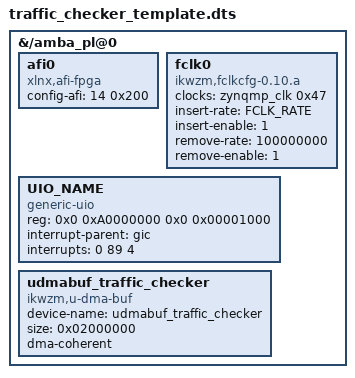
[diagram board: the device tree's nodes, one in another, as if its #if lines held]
#ifndef FPGA_REGION
#error "FPGA_REGION is not defined."
#endif

#if     defined(S_AXI_TYPE_ACP_128)
#define FIRMWARE_NAME "traffic_checker_acp_128.bin"
#define UIO_NAME      uio_traffic_checker_acp
#define DMA_COHERENT  1
#elif   defined(S_AXI_TYPE_HPC_128)
#define FIRMWARE_NAME "traffic_checker_hpc_128.bin"
#define UIO_NAME      uio_traffic_checker_hpc
#define DMA_COHERENT  1
#elif   defined(S_AXI_TYPE_HP_128)
#define FIRMWARE_NAME "traffic_checker_hp_128.bin"
#define UIO_NAME      uio_traffic_checker_hp
#define DMA_COHERENT  0
#else
#error "S_AXI_TYPE is not defined."
#endif

#if     defined(FCLK_RATE_250MHz)
#define FCLK_RATE      "250000000"
#elif   defined(FCLK_RATE_100MHz)
#define FCLK_RATE      "100000000"
#else
#error "FCLK_RATE is not defined."
#endif

/dts-v1/; /plugin/;
/ {
	fragment@0 {
		target-path = FPGA_REGION;
		__overlay__ {
			firmware-name = FIRMWARE_NAME;
		};
	};
	fragment@1 {
		target-path = "/amba_pl@0";
		__overlay__ {
			afi0 {
				compatible    = "xlnx,afi-fpga";
				config-afi    = <14 0x200>;
			};
#ifdef FCLK_RATE			
			fclk0 {
				compatible    = "ikwzm,fclkcfg-0.10.a";
				clocks        = <&zynqmp_clk 0x47>;
				insert-rate   = FCLK_RATE;
				insert-enable = <1>;
				remove-rate   = "100000000";
				remove-enable = <1>;
			};
#endif
		};
	};
	fragment@2 {
		target-path = "/amba_pl@0";
		#address-cells = <2>;
		#size-cells = <2>;

		__overlay__ {
			#address-cells = <2>;
			#size-cells = <2>;

#ifdef DRV_TYPE_UIO
			UIO_NAME {
				compatible = "generic-uio";
				reg = <0x0 0xA0000000 0x0 0x00001000>;
				interrupt-parent = <&gic>;
				interrupts = <0 89 4>;
			};
			udmabuf_traffic_checker {
				compatible  = "ikwzm,u-dma-buf";
				device-name = "udmabuf_traffic_checker";
				size = <0x02000000>;
#if (DMA_COHERENT == 1)
				dma-coherent;
#endif
			};
		};
#endif
#ifdef DRV_TYPE_V4L2
			vb2_test {
				compatible = "ikwzm,vb2-test";
				reg = <0x0 0xA0000000 0x0 0x00001000>;
				interrupt-parent = <&gic>;
				interrupts = <0 89 4>;
#if (DMA_COHERENT == 1)
				dma-coherent;
#endif
			};
#endif
	};
};
